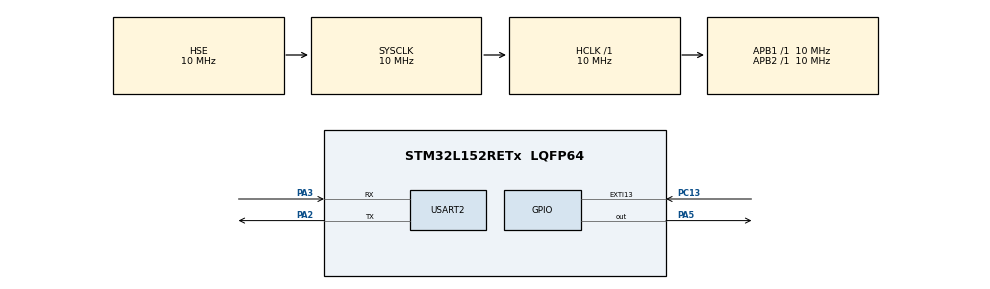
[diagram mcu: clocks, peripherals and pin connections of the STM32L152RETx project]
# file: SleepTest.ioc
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Mcu.Family=STM32L1
Mcu.Name=STM32L152RETx
Mcu.Package=LQFP64
NVIC.EXTI15_10_IRQn=true\:0\:0\:false\:false\:true\:true\:true
NVIC.PriorityGroup=NVIC_PRIORITYGROUP_4
NVIC.USART2_IRQn=true\:0\:0\:false\:false\:true\:true\:true
PA13.Mode=Serial_Wire
PA13.Signal=SYS_JTMS-SWDIO
PA14.Mode=Serial_Wire
PA14.Signal=SYS_JTCK-SWCLK
PA2.Mode=Asynchronous
PA2.Signal=USART2_TX
PA3.Mode=Asynchronous
PA3.Signal=USART2_RX
PA5.Signal=GPIO_Output
PC13-WKUP2.Signal=GPXTI13
PH0-OSC_IN.Mode=HSE-External-Oscillator
PH0-OSC_IN.Signal=RCC_OSC_IN
PH1-OSC_OUT.Mode=HSE-External-Oscillator
PH1-OSC_OUT.Signal=RCC_OSC_OUT
ProjectManager.HeapSize=0x200
ProjectManager.StackSize=0x400
ProjectManager.TargetToolchain=MDK-ARM V5.27
RCC.48MHZClocksFreq_Value=15000000
RCC.AHBFreq_Value=10000000
RCC.APB1Freq_Value=10000000
RCC.APB1TimFreq_Value=10000000
RCC.APB2Freq_Value=10000000
RCC.APB2TimFreq_Value=10000000
RCC.HCLKFreq_Value=10000000
RCC.HSE_VALUE=10000000
RCC.HSI_VALUE=16000000
RCC.LSE_VALUE=32768
RCC.MSI_VALUE=2097000
RCC.PLLSourceVirtual=RCC_PLLSOURCE_HSE
RCC.SYSCLKFreq_VALUE=10000000
RCC.SYSCLKSource=RCC_SYSCLKSOURCE_HSE
RCC.VCOOutputFreq_Value=30000000
USART2.VirtualMode=VM_ASYNC
board=custom

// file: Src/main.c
/* USER CODE BEGIN Header */
/**
  ******************************************************************************
  * @file           : main.c
  * @brief          : Main program body
  ******************************************************************************
  * @attention
  *
  * <h2><center>&copy; Copyright (c) 2020 STMicroelectronics.
  * All rights reserved.</center></h2>
  *
  * This software component is licensed by ST under BSD 3-Clause license,
  * the "License"; You may not use this file except in compliance with the
  * License. You may obtain a copy of the License at:
  *                        opensource.org/licenses/BSD-3-Clause
  *
  ******************************************************************************
  */
/* USER CODE END Header */

#include "main.h"
#include <stdio.h>

UART_HandleTypeDef huart2;

/* USER CODE BEGIN PV */
char Msg1[15] = {0};
/* USER CODE END PV */

void SystemClock_Config(void);
static void MX_GPIO_Init(void);
static void MX_USART2_UART_Init(void);
/* USER CODE BEGIN PFP */
void GOTHEFUCKTOSLEEP();
/* USER CODE END PFP */

/* USER CODE BEGIN 0 */
	int toggle = 1;
/* USER CODE END 0 */

int main(void)
{

  /* MCU Configuration--------------------------------------------------------*/

  /* Reset of all peripherals, Initializes the Flash interface and the Systick. */
  HAL_Init();

  /* Configure the system clock */
  SystemClock_Config();

  /* Initialize all configured peripherals */
  MX_GPIO_Init();
  MX_USART2_UART_Init();

  /* Infinite loop */
  while (1)
  {
		snprintf((char *)Msg1, sizeof(Msg1), "\r\nSleep soon\r\n");
	  HAL_UART_Transmit(&huart2, (uint8_t *) Msg1, sizeof(Msg1), 1);
		HAL_GPIO_WritePin(GPIOA, GPIO_PIN_5, GPIO_PIN_SET);
		HAL_Delay(2500);

		HAL_GPIO_WritePin(GPIOA, GPIO_PIN_5, GPIO_PIN_RESET);

		GOTHEFUCKTOSLEEP();

		snprintf((char *)Msg1, sizeof(Msg1), "\r\n Woke Up\r\n");
	  HAL_UART_Transmit(&huart2, (uint8_t *) Msg1, sizeof(Msg1), 1);

		for(int i = 0; i < 5; ++i){
			HAL_GPIO_TogglePin(GPIOA, GPIO_PIN_5);
			HAL_Delay(150);
		}
    /* USER CODE BEGIN 3 */
  }
    /* USER CODE BEGIN 3 */
    /* USER CODE BEGIN 3 */
  /* USER CODE END 3 */
}

void SystemClock_Config(void)
{
  RCC_OscInitTypeDef RCC_OscInitStruct = {0};
  RCC_ClkInitTypeDef RCC_ClkInitStruct = {0};

  /** Configure the main internal regulator output voltage
  */
  __HAL_PWR_VOLTAGESCALING_CONFIG(PWR_REGULATOR_VOLTAGE_SCALE1);
  /** Initializes the CPU, AHB and APB busses clocks
  */
  RCC_OscInitStruct.OscillatorType = RCC_OSCILLATORTYPE_HSE;
  RCC_OscInitStruct.HSEState = RCC_HSE_ON;
  RCC_OscInitStruct.PLL.PLLState = RCC_PLL_NONE;
  if (HAL_RCC_OscConfig(&RCC_OscInitStruct) != HAL_OK)
  {
    Error_Handler();
  }
  /** Initializes the CPU, AHB and APB busses clocks
  */
  RCC_ClkInitStruct.ClockType = RCC_CLOCKTYPE_HCLK|RCC_CLOCKTYPE_SYSCLK
                              |RCC_CLOCKTYPE_PCLK1|RCC_CLOCKTYPE_PCLK2;
  RCC_ClkInitStruct.SYSCLKSource = RCC_SYSCLKSOURCE_HSE;
  RCC_ClkInitStruct.AHBCLKDivider = RCC_SYSCLK_DIV1;
  RCC_ClkInitStruct.APB1CLKDivider = RCC_HCLK_DIV1;
  RCC_ClkInitStruct.APB2CLKDivider = RCC_HCLK_DIV1;

  if (HAL_RCC_ClockConfig(&RCC_ClkInitStruct, FLASH_LATENCY_0) != HAL_OK)
  {
    Error_Handler();
  }
}

static void MX_USART2_UART_Init(void)
{

  huart2.Instance = USART2;
  huart2.Init.BaudRate = 115200;
  huart2.Init.WordLength = UART_WORDLENGTH_8B;
  huart2.Init.StopBits = UART_STOPBITS_1;
  huart2.Init.Parity = UART_PARITY_NONE;
  huart2.Init.Mode = UART_MODE_TX_RX;
  huart2.Init.HwFlowCtl = UART_HWCONTROL_NONE;
  huart2.Init.OverSampling = UART_OVERSAMPLING_16;
  if (HAL_UART_Init(&huart2) != HAL_OK)
  {
    Error_Handler();
  }

}

static void MX_GPIO_Init(void)
{
  GPIO_InitTypeDef GPIO_InitStruct = {0};

  /* GPIO Ports Clock Enable */
  __HAL_RCC_GPIOC_CLK_ENABLE();
  __HAL_RCC_GPIOH_CLK_ENABLE();
  __HAL_RCC_GPIOA_CLK_ENABLE();

  /*Configure GPIO pin Output Level */
  HAL_GPIO_WritePin(GPIOA, GPIO_PIN_5, GPIO_PIN_RESET);

  /*Configure GPIO pin : PC13 */
  GPIO_InitStruct.Pin = GPIO_PIN_13;
  GPIO_InitStruct.Mode = GPIO_MODE_IT_RISING;
  GPIO_InitStruct.Pull = GPIO_NOPULL;
  HAL_GPIO_Init(GPIOC, &GPIO_InitStruct);

  /*Configure GPIO pin : PA5 */
  GPIO_InitStruct.Pin = GPIO_PIN_5;
  GPIO_InitStruct.Mode = GPIO_MODE_OUTPUT_PP;
  GPIO_InitStruct.Pull = GPIO_NOPULL;
  GPIO_InitStruct.Speed = GPIO_SPEED_FREQ_LOW;
  HAL_GPIO_Init(GPIOA, &GPIO_InitStruct);

  /* EXTI interrupt init*/
  HAL_NVIC_SetPriority(EXTI15_10_IRQn, 0, 0);
  HAL_NVIC_EnableIRQ(EXTI15_10_IRQn);

}

/* USER CODE BEGIN 4 */

void HAL_GPIO_EXTI_Callback(uint16_t GPIO_Pin)
{
  if (GPIO_Pin == GPIO_PIN_13)
  {
		/*
		snprintf((char *)Msg1, sizeof(Msg1), "\r\nZZZZZZ\r\n");
		HAL_UART_Transmit(&huart2, (uint8_t *) Msg1, sizeof(Msg1), 1);
		HAL_PWR_EnableSleepOnExit();
		HAL_SuspendTick();
		HAL_PWR_EnterSLEEPMode(PWR_MAINREGULATOR_ON, PWR_SLEEPENTRY_WFI);
		*/
		//HAL_ResumeTick();
  }
}

void GOTHEFUCKTOSLEEP(void){
		HAL_SuspendTick();

		HAL_PWR_EnterSLEEPMode(PWR_MAINREGULATOR_ON, PWR_SLEEPENTRY_WFI);

		HAL_ResumeTick();

}

/* USER CODE END 4 */

void Error_Handler(void)
{
}

/************************ (C) COPYRIGHT STMicroelectronics *****END OF FILE****/
